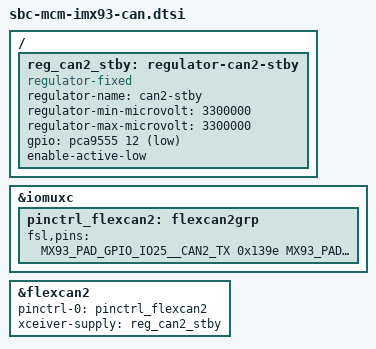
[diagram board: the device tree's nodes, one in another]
// SPDX-License-Identifier: (GPL-2.0+ OR MIT)
/*
 * Copyright 2024 Compulab
 */

/ {
	reg_can2_stby: regulator-can2-stby {
		compatible = "regulator-fixed";
		regulator-name = "can2-stby";
		regulator-min-microvolt = <3300000>;
		regulator-max-microvolt = <3300000>;
		gpio = <&pca9555 12 GPIO_ACTIVE_LOW>;
		enable-active-low;
	};
};

&iomuxc {
	pinctrl_flexcan2: flexcan2grp {
		fsl,pins = <
			MX93_PAD_GPIO_IO25__CAN2_TX	0x139e
			MX93_PAD_GPIO_IO27__CAN2_RX	0x139e
		>;
	};
};

&flexcan2 {
	pinctrl-names = "default";
	pinctrl-0 = <&pinctrl_flexcan2>;
	xceiver-supply = <&reg_can2_stby>;
	status = "okay";
};
